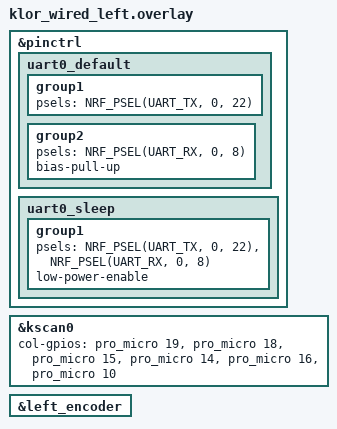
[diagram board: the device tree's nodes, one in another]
#include "klor_wired.dtsi"

/* TRRS routes two data pins (no crossover on PCB):
 *   TRRS pad 3 (net "RX") = pro_micro 4 = P0.22
 *   TRRS pad 4 (net "TX") = pro_micro 0 = P0.08
 * Left: TX on P0.22, RX on P0.08
 * Right: TX on P0.08, RX on P0.22 (software crossover) */
&pinctrl {
	uart0_default: uart0_default {
		group1 {
			psels = <NRF_PSEL(UART_TX, 0, 22)>;
		};
		group2 {
			psels = <NRF_PSEL(UART_RX, 0, 8)>;
			bias-pull-up;
		};
	};

	uart0_sleep: uart0_sleep {
		group1 {
			psels = <NRF_PSEL(UART_TX, 0, 22)>,
				<NRF_PSEL(UART_RX, 0, 8)>;
			low-power-enable;
		};
	};
};

&kscan0 {
	col-gpios
		= <&pro_micro 19 GPIO_ACTIVE_HIGH>
		, <&pro_micro 18 GPIO_ACTIVE_HIGH>
		, <&pro_micro 15 GPIO_ACTIVE_HIGH>
		, <&pro_micro 14 GPIO_ACTIVE_HIGH>
		, <&pro_micro 16 GPIO_ACTIVE_HIGH>
		, <&pro_micro 10 GPIO_ACTIVE_HIGH>
		;
};

&left_encoder {
	status = "okay";
};
